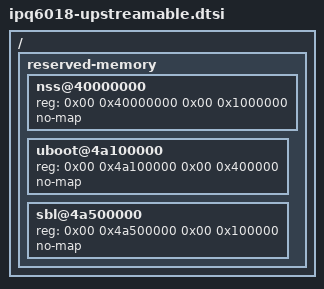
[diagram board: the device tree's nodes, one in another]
/ {
	reserved-memory {
		#address-cells = <2>;
		#size-cells = <2>;
		ranges;

		nss@40000000 {
			reg = <0x00 0x40000000 0x00 0x1000000>;
			no-map;
		};

		uboot@4a100000 {
			reg = <0x00 0x4a100000 0x00 0x400000>;
			no-map;
		};

		sbl@4a500000 {
			reg = <0x00 0x4a500000 0x00 0x100000>;
			no-map;
		};
	};
};
